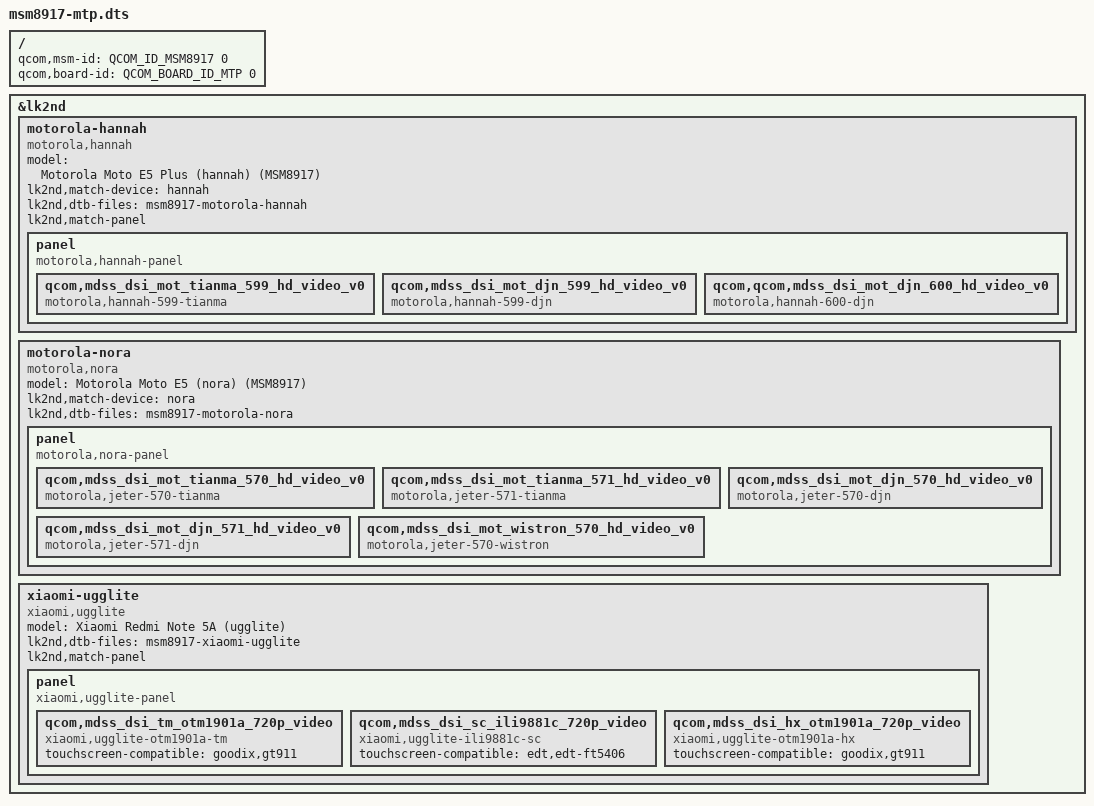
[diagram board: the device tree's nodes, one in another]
// SPDX-License-Identifier: BSD-3-Clause

/dts-v1/;

#include <skeleton64.dtsi>
#include <lk2nd.dtsi>

/ {
	qcom,msm-id = <QCOM_ID_MSM8917 0>;
	qcom,board-id = <QCOM_BOARD_ID_MTP 0>;
};

&lk2nd {
	motorola-hannah {
		model = "Motorola Moto E5 Plus (hannah) (MSM8917)";
		compatible = "motorola,hannah";
		lk2nd,match-device = "hannah";

		lk2nd,dtb-files = "msm8917-motorola-hannah";

		lk2nd,match-panel;
		panel {
			compatible = "motorola,hannah-panel", "lk2nd,panel";
			qcom,mdss_dsi_mot_tianma_599_hd_video_v0 {
				compatible = "motorola,hannah-599-tianma";
			};

			qcom,mdss_dsi_mot_djn_599_hd_video_v0 {
				compatible = "motorola,hannah-599-djn";
			};

			qcom,qcom,mdss_dsi_mot_djn_600_hd_video_v0 {
				compatible = "motorola,hannah-600-djn";
			};
		};
	};

	motorola-nora {
		model = "Motorola Moto E5 (nora) (MSM8917)";
		compatible = "motorola,nora";
		lk2nd,match-device = "nora";

		lk2nd,dtb-files = "msm8917-motorola-nora";

		panel {
			compatible = "motorola,nora-panel", "lk2nd,panel";

			qcom,mdss_dsi_mot_tianma_570_hd_video_v0 {
				compatible = "motorola,jeter-570-tianma";
			};
			qcom,mdss_dsi_mot_tianma_571_hd_video_v0 {
				compatible = "motorola,jeter-571-tianma";
			};
			qcom,mdss_dsi_mot_djn_570_hd_video_v0 {
				compatible = "motorola,jeter-570-djn";
			};
			qcom,mdss_dsi_mot_djn_571_hd_video_v0 {
				compatible = "motorola,jeter-571-djn";
			};
			qcom,mdss_dsi_mot_wistron_570_hd_video_v0 {
				compatible = "motorola,jeter-570-wistron";
			};
		};
	};

	xiaomi-ugglite {
		model = "Xiaomi Redmi Note 5A (ugglite)";
		compatible = "xiaomi,ugglite";

		lk2nd,dtb-files = "msm8917-xiaomi-ugglite";

		lk2nd,match-panel;
		panel {
			compatible = "xiaomi,ugglite-panel", "lk2nd,panel";

			qcom,mdss_dsi_tm_otm1901a_720p_video {
				compatible = "xiaomi,ugglite-otm1901a-tm";
				touchscreen-compatible = "goodix,gt911";
			};
			qcom,mdss_dsi_sc_ili9881c_720p_video {
				compatible = "xiaomi,ugglite-ili9881c-sc";
				touchscreen-compatible = "edt,edt-ft5406";
			};
			qcom,mdss_dsi_hx_otm1901a_720p_video {
				compatible = "xiaomi,ugglite-otm1901a-hx";
				touchscreen-compatible = "goodix,gt911";
			};
		};
	};
};
